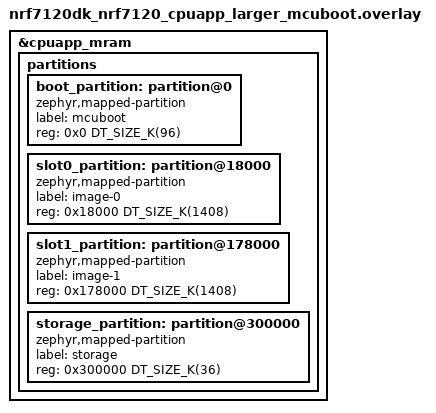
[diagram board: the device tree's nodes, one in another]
/*
 * Copyright (c) 2026 Nordic Semiconductor ASA
 *
 * SPDX-License-Identifier: LicenseRef-Nordic-5-Clause
 */

/delete-node/ &boot_partition;
/delete-node/ &slot0_partition;
/delete-node/ &slot1_partition;
/delete-node/ &storage_partition;

&cpuapp_mram {
	partitions {
		boot_partition: partition@0 {
			compatible = "zephyr,mapped-partition";
			label = "mcuboot";
			reg = <0x0 DT_SIZE_K(96)>;
		};

		slot0_partition: partition@18000 {
			compatible = "zephyr,mapped-partition";
			label = "image-0";
			reg = <0x18000 DT_SIZE_K(1408)>;
		};

		slot1_partition: partition@178000 {
			compatible = "zephyr,mapped-partition";
			label = "image-1";
			reg = <0x178000 DT_SIZE_K(1408)>;
		};

		storage_partition: partition@300000 {
			compatible = "zephyr,mapped-partition";
			label = "storage";
			reg = <0x300000 DT_SIZE_K(36)>;
		};
	};
};
